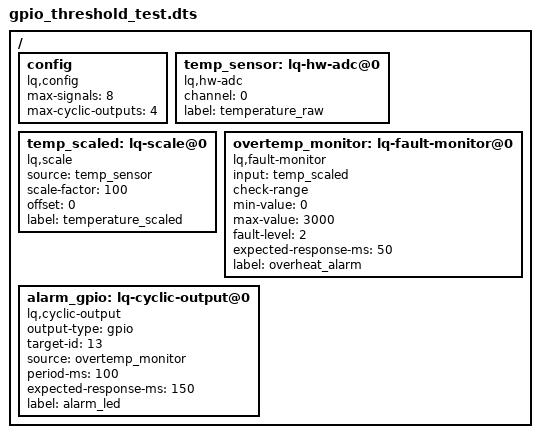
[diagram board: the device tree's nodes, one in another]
/*
 * Simple GPIO threshold test
 * When ADC value > 3000, set GPIO high
 */

/ {
    config {
        compatible = "lq,config";
        max-signals = <8>;
        max-cyclic-outputs = <4>;
    };

    /* ADC input - reads analog sensor value */
    temp_sensor: lq-hw-adc@0 {
        compatible = "lq,hw-adc";
        channel = <0>;
        label = "temperature_raw";
    };

    /* Scale raw ADC value to temperature in decidegrees C */
    temp_scaled: lq-scale@0 {
        compatible = "lq,scale";
        source = <&temp_sensor>;
        scale-factor = <100>;    /* ADC units to decidegrees */
        offset = <0>;
        label = "temperature_scaled";
    };

    /* Fault monitor: if temperature > 3000 (300.0°C), set alarm signal */
    overtemp_monitor: lq-fault-monitor@0 {
        compatible = "lq,fault-monitor";
        input = <&temp_scaled>;
        check-range;
        min-value = <0>;
        max-value = <3000>;      /* Max 300.0°C */
        fault-level = <2>;
        expected-response-ms = <50>;  /* Fault detection should be fast */
        label = "overheat_alarm";
    };

    /* GPIO output: cyclic check of alarm signal, toggle GPIO */
    alarm_gpio: lq-cyclic-output@0 {
        compatible = "lq,cyclic-output";
        output-type = "gpio";
        target-id = <13>;        /* GPIO pin 13 (LED) */
        source = <&overtemp_monitor>;
        period-ms = <100>;       /* Check every 100ms */
        expected-response-ms = <150>;  /* Should respond within period + margin */
        label = "alarm_led";
    };
};
